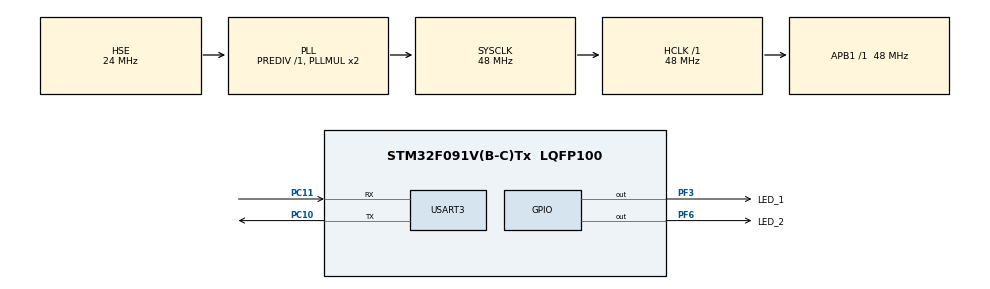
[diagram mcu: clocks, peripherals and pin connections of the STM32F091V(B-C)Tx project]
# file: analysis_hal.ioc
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Mcu.Family=STM32F0
Mcu.Name=STM32F091V(B-C)Tx
Mcu.Package=LQFP100
NVIC.TIM6_DAC_IRQn=true\:0\:0\:false\:false\:true\:true\:true\:true
NVIC.USART3_8_IRQn=true\:0\:0\:false\:false\:true\:true\:true\:true
PC10.Mode=Asynchronous
PC10.Signal=USART3_TX
PC11.Mode=Asynchronous
PC11.Signal=USART3_RX
PF0-OSC_IN.Mode=HSE-External-Oscillator
PF0-OSC_IN.Signal=RCC_OSC_IN
PF1-OSC_OUT.Mode=HSE-External-Oscillator
PF1-OSC_OUT.Signal=RCC_OSC_OUT
PF3.GPIO_Label=LED_1
PF3.GPIO_PuPd=GPIO_PULLDOWN
PF3.Signal=GPIO_Output
PF6.GPIO_Label=LED_2
PF6.GPIO_PuPd=GPIO_PULLDOWN
PF6.Signal=GPIO_Output
ProjectManager.HeapSize=0x200
ProjectManager.StackSize=0x400
ProjectManager.TargetToolchain=STM32CubeIDE
RCC.AHBFreq_Value=48000000
RCC.APB1Freq_Value=48000000
RCC.APB1TimFreq_Value=48000000
RCC.HCLKFreq_Value=48000000
RCC.HSE_VALUE=24000000
RCC.PLLSourceVirtual=RCC_PLLSOURCE_HSE
RCC.SYSCLKFreq_VALUE=48000000
RCC.SYSCLKSource=RCC_SYSCLKSOURCE_PLLCLK
TIM6.Period=1000-1
TIM6.Prescaler=48-1
USART3.VirtualMode-Asynchronous=VM_ASYNC
VP_TIM6_VS_ClockSourceINT.Mode=Enable_Timer
board=custom

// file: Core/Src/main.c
/* USER CODE BEGIN Header */
/**
  ******************************************************************************
  * @file           : main.c
  * @brief          : Main program body
  ******************************************************************************
  * @attention
  *
  * Copyright (c) 2023 STMicroelectronics.
  * All rights reserved.
  *
  * This software is licensed under terms that can be found in the LICENSE file
  * in the root directory of this software component.
  * If no LICENSE file comes with this software, it is provided AS-IS.
  *
  ******************************************************************************
  */
/* USER CODE END Header */
#include "main.h"
#include "tim.h"
#include "usart.h"
#include "gpio.h"

/* USER CODE BEGIN Includes */
#include <stdio.h>
/* USER CODE END Includes */

/* USER CODE BEGIN PM */

#ifdef __GNUC__
/* With GCC, small printf (option LD Linker->Libraries->Small printf
   set to 'Yes') calls __io_putchar() */
int __io_putchar(int ch)
#else
int fputc(int ch, FILE *f)
#endif /* __GNUC__ */
{

  // HAL_UART_Transmit_IT(&huart3, (uint8_t*)&ch, 1);
  HAL_UART_Transmit(&huart3, (uint8_t *)&ch, 1, 0xFFFF);

  return ch;
}

/* USER CODE END PM */

void SystemClock_Config(void);

int main(void)
{

  /* MCU Configuration--------------------------------------------------------*/

  /* Reset of all peripherals, Initializes the Flash interface and the Systick. */
  HAL_Init();

  /* Configure the system clock */
  SystemClock_Config();

  /* Initialize all configured peripherals */
  MX_GPIO_Init();
  MX_TIM6_Init();
  MX_USART3_UART_Init();

  /* Infinite loop */
  /* USER CODE BEGIN WHILE */
  HAL_GPIO_WritePin(LED_1_GPIO_Port, LED_1_Pin, GPIO_PIN_SET);
  printf("Hello, this is 'analysis of HAL project' \r\n");
  while (1)
  {
    if (tim_check(1000))
    {
      HAL_GPIO_TogglePin(LED_2_GPIO_Port, LED_2_Pin);
    }
    /* USER CODE END WHILE */

  }
}

void SystemClock_Config(void)
{
  RCC_OscInitTypeDef RCC_OscInitStruct = {0};
  RCC_ClkInitTypeDef RCC_ClkInitStruct = {0};
  RCC_PeriphCLKInitTypeDef PeriphClkInit = {0};

  /** Initializes the RCC Oscillators according to the specified parameters
  * in the RCC_OscInitTypeDef structure.
  */
  RCC_OscInitStruct.OscillatorType = RCC_OSCILLATORTYPE_HSE;
  RCC_OscInitStruct.HSEState = RCC_HSE_ON;
  RCC_OscInitStruct.PLL.PLLState = RCC_PLL_ON;
  RCC_OscInitStruct.PLL.PLLSource = RCC_PLLSOURCE_HSE;
  RCC_OscInitStruct.PLL.PLLMUL = RCC_PLL_MUL2;
  RCC_OscInitStruct.PLL.PREDIV = RCC_PREDIV_DIV1;
  if (HAL_RCC_OscConfig(&RCC_OscInitStruct) != HAL_OK)
  {
    Error_Handler();
  }

  /** Initializes the CPU, AHB and APB buses clocks
  */
  RCC_ClkInitStruct.ClockType = RCC_CLOCKTYPE_HCLK|RCC_CLOCKTYPE_SYSCLK
                              |RCC_CLOCKTYPE_PCLK1;
  RCC_ClkInitStruct.SYSCLKSource = RCC_SYSCLKSOURCE_PLLCLK;
  RCC_ClkInitStruct.AHBCLKDivider = RCC_SYSCLK_DIV1;
  RCC_ClkInitStruct.APB1CLKDivider = RCC_HCLK_DIV1;

  if (HAL_RCC_ClockConfig(&RCC_ClkInitStruct, FLASH_LATENCY_1) != HAL_OK)
  {
    Error_Handler();
  }
  PeriphClkInit.PeriphClockSelection = RCC_PERIPHCLK_USART3;
  PeriphClkInit.Usart3ClockSelection = RCC_USART3CLKSOURCE_PCLK1;
  if (HAL_RCCEx_PeriphCLKConfig(&PeriphClkInit) != HAL_OK)
  {
    Error_Handler();
  }
}

void Error_Handler(void)
{
  __disable_irq();
  while (1)
  {
  }
}
